# no_ve_golden_model: IP-XACT component
VLNV cadence:test:no_ve_golden_model:1.4

## Address spaces and blocks
am0.rf1: base 0x1000, range 0x100, width 8
am0.rf2: base 0x2000, range 0x100, width 8

## Registers
Registers are 8-bit, access not given, reset 0x0 unless marked. A register's access mark holds for its fields unless they carry their own. Offsets are from the block's base; lines under a group give offsets from that group; [hi:lo] are bit positions; {n}, {i} and the like mark numbered series; 'fields as' and 'values as' point back to an identical list; <NAME> marks a mode.

## am0.rf1
Base 0x00001000
0x00 reg0 wo — register with no fields. No access is defined - In logfile the access of the field created should be write-only (and not the default read-write) because it inherits access from the parent register.
0x01 reg1 wo — register with one field. Should look exactly the same as the previous register (except type specific parameters)
  [7:0] reg1_f
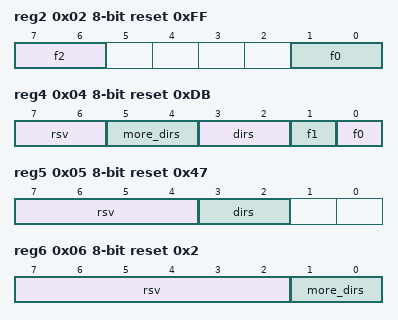
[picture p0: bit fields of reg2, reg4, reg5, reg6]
0x02 reg2 reset 0xFF — register with unused offset in the middle. Should create reserved field in offset 2-5. In logfile register's access_policy should be RW. f0 - access is RW, cov: full, hard_reset: ON/3, soft_reset: OFF/0. rsv- access is RSVD, cov: none, hard_reset: ON/'hF, soft_reset: OFF/0. f2 - access is RW, cov: full, hard_reset: ON/3, soft_reset: OFF/0. Update mask for the register: 'hc3. Compare mask for the register: 'hff. one warning: No field at offset 2 that (auto generated) while a reset mask for 'Hard Reset' value is specified for it.
  [7:6] f2 rw, [1:0] f0
0x03 reg3 reset 0x38 — register with unused offsets at both edges of register. Should create reserved fields in offset 0-2 and 6-7. rsv - access is RSVD, cov: none, hard_reset: OFF/0, soft_reset: OFF/0. f0 - access is RW (default), cov: full, hard_reset: ON/7, soft_reset: OFF/0. rsv1- access is RSVD, cov: none, hard_reset: OFF/0, soft_reset: OFF/0. Update mask for the register: 'h38. Compare mask for the register: 'hff.
  [5:3] f0
0x04 reg4 reset 0xDB (reset mask 0xCE) — register with mixed access policies. f0 - access is RW, cov: full, hard_reset: OFF/1, soft_reset: OFF/0. f1 - access is RW, cov: full, hard_reset: ON/1, soft_reset: OFF/0. dirs - access is WO, cov: full, hard_reset: ON/2, soft_reset: OFF/0. more_dirs - access is RO, cov: full, hard_reset: OFF/1, soft_reset: OFF/0. rsv - access is RW, cov: all, hard_reset: ON/3, soft_reset: OFF/0. rsv is not recognized as 'reserved'. Update mask for the register: 'hc. Compare mask for the register: 'hf0.
  [7:6] rsv
  [5:4] more_dirs ro
    0=north_east; 1=south_west; 2=south_east; 3=north_west
  [3:2] dirs wo
    0=north; 1=south; 2=east; 3=west
  [1] f1
  [0] f0
0x05 reg5 wo reset 0x47 (reset mask 0xF) — reuse directions enumeration defined in reg4. This will cause a new instance of a modified enumeration. rsv1 - access: RSVD, cov: none, hard_reset: ON/3, soft_reset: OFF/0. dirs - access is WO (inherit from reg), cov: full, hard_reset: ON/1, soft_reset: OFF/0. rsv - access is WO (inherit from reg), cov: full, hard_reset: OFF/4, soft_reset: OFF/0. rsv is not recognized as 'reserved'. Update mask for the register: 'fc. Compare mask for the register: 'h3. Warning: x4 Enumeration name/value reusability. hard reset value exist for unspecified offset
  [7:4] rsv
  [3:2] dirs
    0=north; 1=south; 2=east; 3=west
0x06 reg6 ro reset 0x2 (reset mask 0x3) — reuse more_directions enumeration defined in reg4 directions - access is RO, cov: full, hard_reset: ON/2, soft_reset: OFF/0. rsv - access is RO, cov: full, hard_reset: OFF/0, soft_reset: OFF/0. rsv is not identified as 'reserved'. Reg access policy in logfile is RO. Update mask for the register: 'h0. Compare mask for the register: 'hff. Warning: x4 Enumeration name/value reusability.
  [7:2] rsv
  [1:0] more_dirs
    0=north_east; 1=south_west; 2=south_east; 3=north_west

## am0.rf2 — use baseAddress of size greater then 32 bits and less then 64bits.
Base 0x00002000
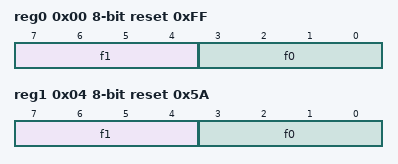
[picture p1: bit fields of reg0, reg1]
0x00 reg0 reset 0xFF (reset mask 0xCC) — register with inconsistent hard reset values per field (field's reset masks are composed of ones AND zeroes) should be defaulted to ON. No soft reset value - should be defaulted to OFF/0. No coverage defined for fields - both default (full coverage). No access is defined for neither fields or register (default to read-write). Hard reset value of both fields is ON/'hf. Warnings: 2x Inconsistency of hard reset mask.
  [7:4] f1, [3:0] f0
0x04 reg1 reset 0x5A — register without reset mask to test CrossOrigen import process.
  [7:4] f1, [3:0] f0
